# dm64lc_cslr_resz_001 register map
Vendor: Texas Instruments
Peripheral module from a debugger description file.
Registers are 32-bit, access not given, reset 0x0 unless marked. A register's access mark holds for its fields unless they carry their own. Offsets are as the file gives them; lines under a group give offsets from that group; [hi:lo] are bit positions; {n}, {i} and the like mark numbered series; 'fields as' and 'values as' point back to an identical list; <NAME> marks a mode.

## RESZ — Resizer (spec version 1.00.w.36)
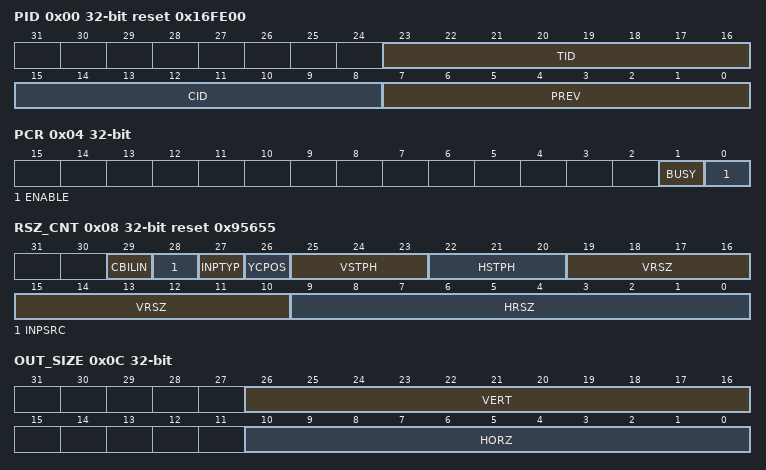
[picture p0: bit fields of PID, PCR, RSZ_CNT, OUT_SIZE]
0x00 PID reset 0x16FE00 — Peripheral Revision and Class Information
  [23:16] TID ro — Peripheral Identification Resizer module
  [15:8] CID ro — Class Identification Video processing front end
  [7:0] PREV ro — Peripheral Revision Number Initial Revision
0x04 PCR — Peripheral Control Register
  [1] BUSY ro — Busy bit
    0=NOTBUSY (No error); 1=BUSY (Error)
  [0] ENABLE rw — Enable Resizer always operates in one-shot mode; programmer must enable resizer for each frame that needs to be resized. Enable bit is reset to 0 once the busy bit turns to 1. The enable bit MUST be the last field written to resize a frame. The enable bit can be written when the resizer is busy.
    0=DISABLE (No error); 1=ENABLE (Error)
0x08 RSZ_CNT reset 0x95655 — Resizer control bits
  [29] CBILIN rw — Chrominance horizontal algorithm Filtering that is same as luminance processing is intended only for downsampling, and bilinear interpolation is intended only for upsampling.
    0=SAME_AS_LUMA (same as luminance processing); 1=BILIN_INTERP (bilinear interpolation)
  [28] INPSRC rw — Input source NOTE: If this field is set to '0' the resizer input will be fed from either the preview engine or the CCDC, but not both. The CCDC and preview engine modules have individual control to feed their output to the resizer input. If both the CCDC and preview engine modules are set to drive the resizer input, the CCDC output takes precedence.
    0=PREVIEW_OR_CCDC (Preview engine); 1=SDRAM
  [27] INPTYP rw — Input type
    0=YUV422_INTERLEAVED (YUV422 color interleaved); 1=COLOR_SEP_8BIT (color separate (8-bit data))
  [26] YCPOS rw — Luminance and chrominance position in 16-bit word
    0=YC; 1=CY
  [25:23] VSTPH rw — Vertical starting phase (0 - 7)
  [22:20] HSTPH rw — Horizontal starting phase (0 - 7)
  [19:10] VRSZ rw — Vertical resizing value (range from 64 - 1024) plus 1 Vertical resizing ratio is 256/VRSZ
  [9:0] HRSZ rw — Horizontal resizing value (range from 64 - 1024) plus 1 Horizontal resizing ratio is 256/HRSZ)
0x0C OUT_SIZE — Output width and height after resizing
  [26:16] VERT rw — Output height (in the vertical direction)
  [10:0] HORZ rw — Output (width in the horizontal direction) The maximum output width cannot be greater than 1280 pixels wide (640 if downsampling greater than 2 is used with 7 filter taps) This value must be EVEN and tne number of bytes written to SDRAM must be a multiple of 16-bytes if the vertical resizing factor is greater than 1x (upsizing)
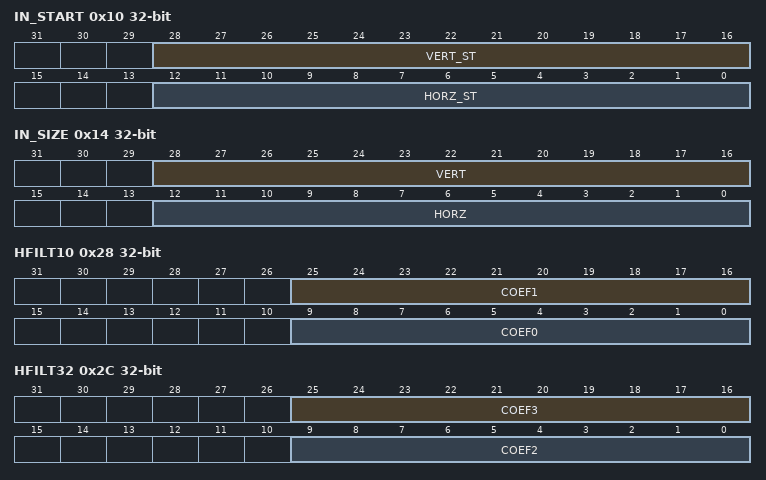
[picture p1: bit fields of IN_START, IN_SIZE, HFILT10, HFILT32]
0x10 IN_START — Input starting information
  [28:16] VERT_ST rw — Vertical starting line This field makes sense when the resizer obtains its input from the preview engine. When the resizer gets its input from SDRAM, this field must be set to 0
  [12:0] HORZ_ST rw — Horizontal starting pixel This field makes sense when the resizer obtains its input from the preview engine. When the resizer gets its input from SDRAM, this field must be set to <= 15 for YUV 16-bit data and <= 31 for 8-bit color separate data Horizontal starting pixel value is in number of pixels if input is from SDRAM. If the input to the resizer is from CCDC/preview engine, this field needs to be programmed as follows: (1) Program this field using number of bytes (twice number of pixels). (2) Change the lowest bit to reflect start position in pixels (effectively change from a value 0 to a value 1 if re-quired)
0x14 IN_SIZE — Input width and height before resizing
  [28:16] VERT rw — Input height (in the vertical direction)
  [12:0] HORZ rw — Input width (in the horizontal direction)
0x18 SDR_INADD rw — Input SDRAM address
  [31:0] SDR_INADD — Input SDRAM address The 5 LSB are treated as zeroes - should be on a 32-byte boundary * This field can be altered even when the resizer is busy. Change will take place only for the next frame. However, note that reading this register will always give the latest value.
0x1C SDR_INOFF — SDRAM offset for the input line
  [15:0] OFFSET rw — Input SDRAM address The 5 LSB are treated as zeroes - should be on a 32-byte boundary * This field can be altered even when the resizer is busy. Change will take place only for the next frame. However, note that reading this register will always give the latest value.
0x20 SDR_OUTADD rw — Output SDRAM address
  [31:0] SDR_OUTADD — Output SDRAM address The 5 LSB are treated as zeroes - should be on a 32-byte boundary For optimal use of SDRAM bandwidth, the SDRAM address should be set on a 256-byte boundary. * This field can be altered even when the resizer is busy. Change will take place only for the next frame. However, note that reading this register will always give the latest value.
0x24 SDR_OUTOFF — SDRAM offset for the output line
  [15:0] OFFSET rw — Offset of each line in the SDRAM The 5 LSB are treated as zeroes - should be on a 32-byte boundary For optimal use of SDRAM bandwidth, the SDRAM line offset should be set on a 256-byte boundary. * This field can be altered even when the resizer is busy. Change will take place only for the next frame. However, note that reading this register will always give the latest value.
0x28 HFILT10 — Horizontal filter coefficients 1 and 0
  [25:16] COEF1 rw — Coefficient - Phase 0, tap 1 (S10Q8 format -> range of -2 to 1.255/256, 1 is 0x100)
  [9:0] COEF0 rw — Coefficient - Phase 0, tap 0 (S10Q8 format -> range of -2 to 1.255/256, 1 is 0x100)
0x2C HFILT32 — Horizontal filter coefficients 3 and 2
  [25:16] COEF3 rw — Coefficient - Phase 0, tap 3 (S10Q8 format -> range of -2 to 1.255/256, 1 is 0x100)
  [9:0] COEF2 rw — Coefficient - Phase 0, tap 2 (S10Q8 format -> range of -2 to 1.255/256, 1 is 0x100)
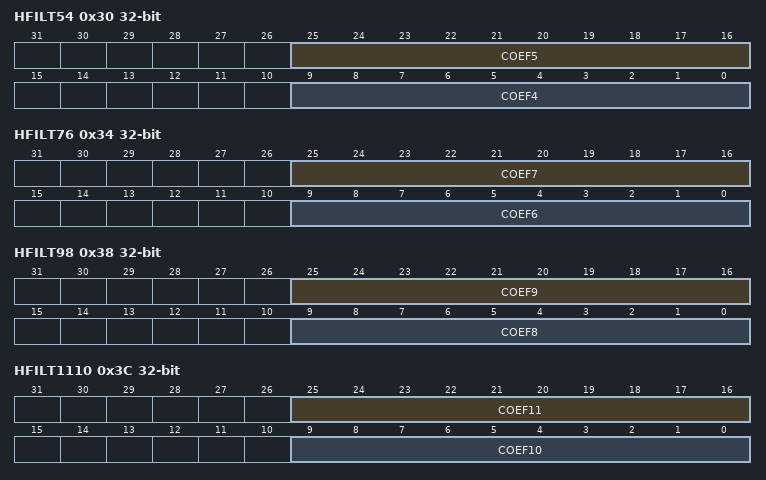
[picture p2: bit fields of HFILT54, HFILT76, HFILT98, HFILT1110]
0x30 HFILT54 — Horizontal filter coefficients 5 and 4
  [25:16] COEF5 rw — Coefficient - Phase 0/1, tap 5/1 (S10Q8 format -> range of -2 to 1.255/256, 1 is 0x100)
  [9:0] COEF4 rw — Coefficient - Phase 0/1, tap 4/0 (S10Q8 format -> range of -2 to 1.255/256, 1 is 0x100)
0x34 HFILT76 — Horizontal filter coefficients 7 and 6
  [25:16] COEF7 rw — Coefficient - Phase 0/1, tap 7/3 (S10Q8 format -> range of -2 to 1.255/256, 1 is 0x100)
  [9:0] COEF6 rw — Coefficient - Phase 0/1, tap 6/2 (S10Q8 format -> range of -2 to 1.255/256, 1 is 0x100)
0x38 HFILT98 — Horizontal filter coefficients 9 and 8
  [25:16] COEF9 rw — Coefficient) - Phase 1/2, tap 1/1 (S10Q8 format -> range of -2 to 1.255/256, 1 is 0x100)
  [9:0] COEF8 rw — Coefficient) - Phase 1/2, tap 0/0 (S10Q8 format -> range of -2 to 1.255/256, 1 is 0x100)
0x3C HFILT1110 — Horizontal filter coefficients 11 and 10
  [25:16] COEF11 rw — Coefficient) - Phase 1/2, tap 3/3 (S10Q8 format -> range of -2 to 1.255/256, 1 is 0x100)
  [9:0] COEF10 rw — Coefficient) - Phase 1/2, tap 2/2 (S10Q8 format -> range of -2 to 1.255/256, 1 is 0x100)
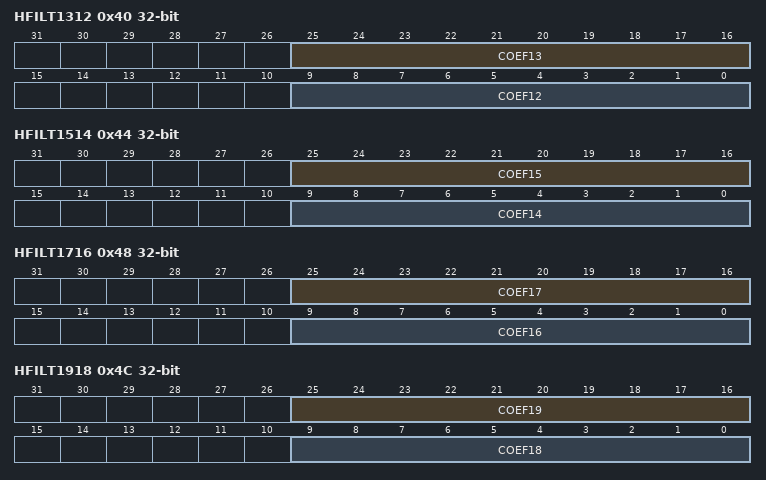
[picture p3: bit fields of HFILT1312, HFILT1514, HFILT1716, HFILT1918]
0x40 HFILT1312 — Horizontal filter coefficients 13 and 12
  [25:16] COEF13 rw — Coefficient) - Phase 1/3, tap 5/1 (S10Q8 format -> range of -2 to 1.255/256, 1 is 0x100)
  [9:0] COEF12 rw — Coefficient) - Phase 1/3, tap 4/0 (S10Q8 format -> range of -2 to 1.255/256, 1 is 0x100)
0x44 HFILT1514 — Horizontal filter coefficients 15 and 14
  [25:16] COEF15 rw — Coefficient) - Phase 1/3, tap 7/3 (S10Q8 format -> range of -2 to 1.255/256, 1 is 0x100)
  [9:0] COEF14 rw — Coefficient) - Phase 1/3, tap 6/2 (S10Q8 format -> range of -2 to 1.255/256, 1 is 0x100)
0x48 HFILT1716 — Horizontal filter coefficients 17 and 16
  [25:16] COEF17 rw — Coefficient) - Phase 2/4, tap 1/1 (S10Q8 format -> range of -2 to 1.255/256, 1 is 0x100)
  [9:0] COEF16 rw — Coefficient) - Phase 2/4, tap 0/0 (S10Q8 format -> range of -2 to 1.255/256, 1 is 0x100)
0x4C HFILT1918 — Horizontal filter coefficients 19 and 18
  [25:16] COEF19 rw — Coefficient) - Phase 2/4, tap 3/3 (S10Q8 format -> range of -2 to 1.255/256, 1 is 0x100)
  [9:0] COEF18 rw — Coefficient) - Phase 2/4, tap 2/2 (S10Q8 format -> range of -2 to 1.255/256, 1 is 0x100)
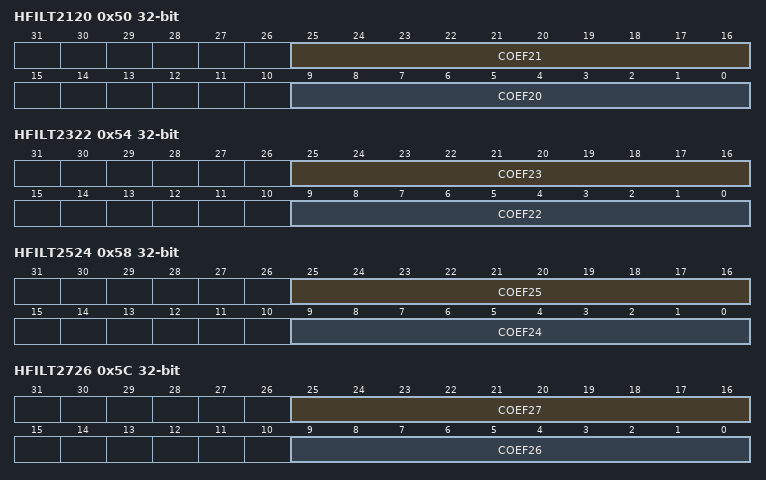
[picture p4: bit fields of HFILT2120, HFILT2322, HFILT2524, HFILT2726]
0x50 HFILT2120 — Horizontal filter coefficients 21 and 20
  [25:16] COEF21 rw — Coefficient) - Phase 2/5, tap 5/1 (S10Q8 format -> range of -2 to 1.255/256, 1 is 0x100)
  [9:0] COEF20 rw — Coefficient) - Phase 2/5, tap 4/0 (S10Q8 format -> range of -2 to 1.255/256, 1 is 0x100)
0x54 HFILT2322 — Horizontal filter coefficients 23 and 22
  [25:16] COEF23 rw — Coefficient) - Phase 2/5, tap 7/3 (S10Q8 format -> range of -2 to 1.255/256, 1 is 0x100)
  [9:0] COEF22 rw — Coefficient) - Phase 2/5, tap 6/2 (S10Q8 format -> range of -2 to 1.255/256, 1 is 0x100)
0x58 HFILT2524 — Horizontal filter coefficients 25 and 24
  [25:16] COEF25 rw — Coefficient) - Phase 3/6, tap 1/1 (S10Q8 format -> range of -2 to 1.255/256, 1 is 0x100)
  [9:0] COEF24 rw — Coefficient) - Phase 3/6, tap 0/0 (S10Q8 format -> range of -2 to 1.255/256, 1 is 0x100)
0x5C HFILT2726 — Horizontal filter coefficients 27 and 26
  [25:16] COEF27 rw — Coefficient) - Phase 3/6, tap 3/3 (S10Q8 format -> range of -2 to 1.255/256, 1 is 0x100)
  [9:0] COEF26 rw — Coefficient) - Phase 3/6, tap 2/2 (S10Q8 format -> range of -2 to 1.255/256, 1 is 0x100)
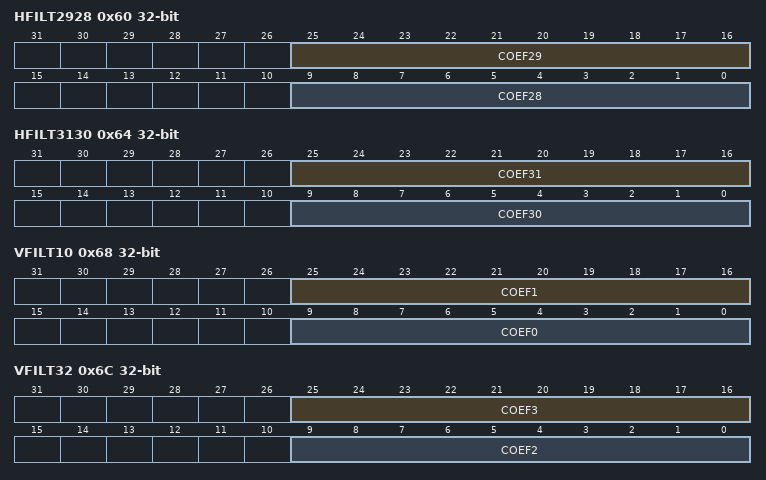
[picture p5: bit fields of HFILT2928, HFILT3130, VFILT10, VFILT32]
0x60 HFILT2928 — Horizontal filter coefficients 29 and 28
  [25:16] COEF29 rw — Coefficient) - Phase 3/7, tap 5/1 (S10Q8 format -> range of -2 to 1.255/256, 1 is 0x100)
  [9:0] COEF28 rw — Coefficient) - Phase 3/7, tap 4/0 (S10Q8 format -> range of -2 to 1.255/256, 1 is 0x100)
0x64 HFILT3130 — Horizontal filter coefficients 31 and 30
  [25:16] COEF31 rw — Coefficient) - Phase 3/7, tap 7/3 (S10Q8 format -> range of -2 to 1.255/256, 1 is 0x100)
  [9:0] COEF30 rw — Coefficient) - Phase 3/7, tap 6/2 (S10Q8 format -> range of -2 to 1.255/256, 1 is 0x100)
0x68 VFILT10 — Vertical filter coefficients 1 and 0
  [25:16] COEF1 rw — Coefficient) - Phase 0, tap 1 (S10Q8 format -> range of -2 to 1.255/256, 1 is 0x100)
  [9:0] COEF0 rw — Coefficient) - Phase 0, tap 0 (S10Q8 format -> range of -2 to 1.255/256, 1 is 0x100)
0x6C VFILT32 — Vertical filter coefficients 3 and 2
  [25:16] COEF3 rw — Coefficient) - Phase 0, tap 3 (S10Q8 format -> range of -2 to 1.255/256, 1 is 0x100)
  [9:0] COEF2 rw — Coefficient) - Phase 0, tap 2 (S10Q8 format -> range of -2 to 1.255/256, 1 is 0x100)
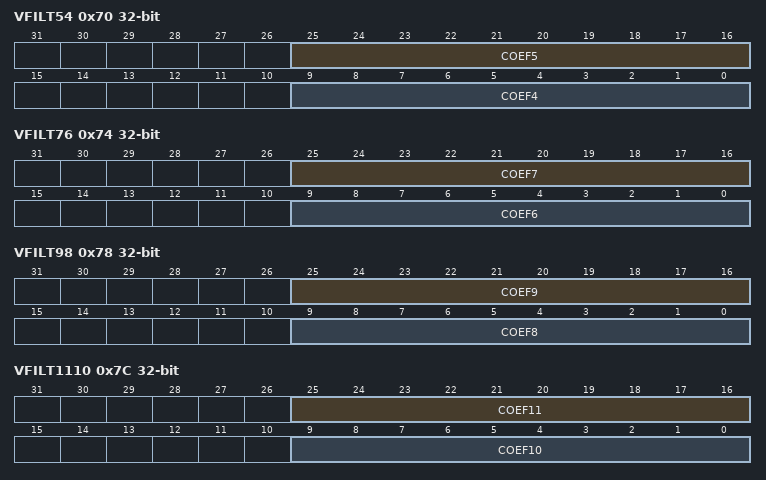
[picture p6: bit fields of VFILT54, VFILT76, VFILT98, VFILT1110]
0x70 VFILT54 — Vertical filter coefficients 5 and 4
  [25:16] COEF5 rw — Coefficient) - Phase 0/1, tap 5/1 (S10Q8 format -> range of -2 to 1.255/256, 1 is 0x100)
  [9:0] COEF4 rw — Coefficient) - Phase 0/1, tap 4/0 (S10Q8 format -> range of -2 to 1.255/256, 1 is 0x100)
0x74 VFILT76 — Vertical filter coefficients 7 and 6
  [25:16] COEF7 rw — Coefficient) - Phase 0/1, tap 7/3 (S10Q8 format -> range of -2 to 1.255/256, 1 is 0x100)
  [9:0] COEF6 rw — Coefficient) - Phase 0/1, tap 6/2 (S10Q8 format -> range of -2 to 1.255/256, 1 is 0x100)
0x78 VFILT98 — Vertical filter coefficients 9 and 8
  fields as HFILT98
0x7C VFILT1110 — Vertical filter coefficients 11 and 10
  fields as HFILT1110
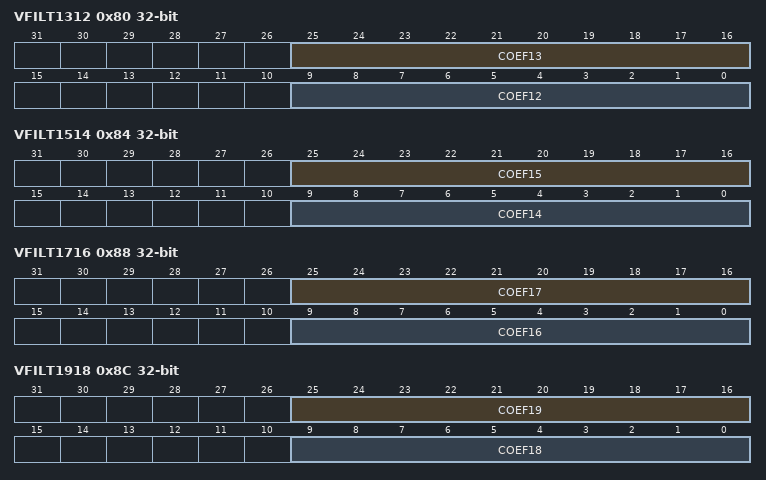
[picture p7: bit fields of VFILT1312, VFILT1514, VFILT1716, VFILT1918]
0x80 VFILT1312 — Vertical filter coefficients 13 and 12
  fields as HFILT1312
0x84 VFILT1514 — Vertical filter coefficients 15 and 14
  fields as HFILT1514
0x88 VFILT1716 — Vertical filter coefficients 17 and 16
  fields as HFILT1716
0x8C VFILT1918 — Vertical filter coefficients 19 and 18
  fields as HFILT1918
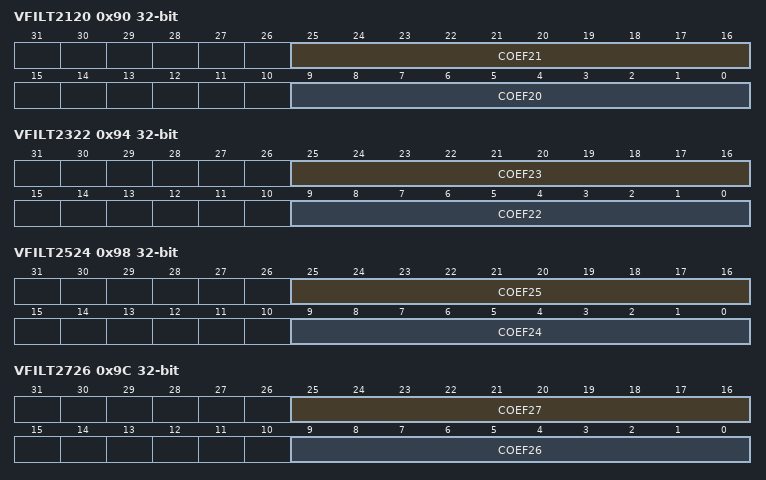
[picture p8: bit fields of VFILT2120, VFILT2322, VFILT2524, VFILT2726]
0x90 VFILT2120 — Vertical filter coefficients 21 and 20
  fields as HFILT2120
0x94 VFILT2322 — Vertical filter coefficients 23 and 22
  fields as HFILT2322
0x98 VFILT2524 — Vertical filter coefficients 25 and 24
  fields as HFILT2524
0x9C VFILT2726 — Vertical filter coefficients 27 and 26
  fields as HFILT2726
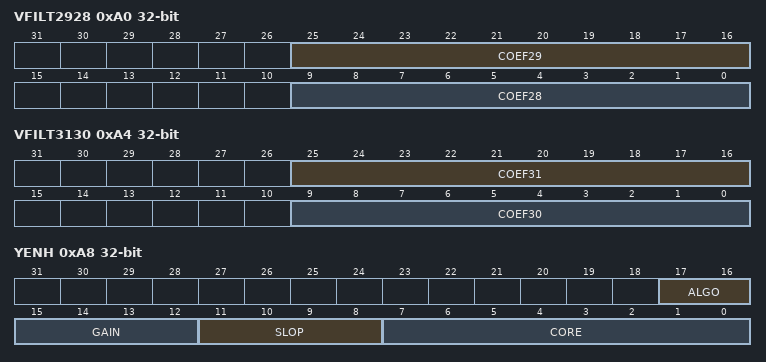
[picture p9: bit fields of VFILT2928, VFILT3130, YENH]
0xA0 VFILT2928 — Vertical filter coefficients 29 and 28
  fields as HFILT2928
0xA4 VFILT3130 — Vertical filter coefficients 31 and 30
  fields as HFILT3130
0xA8 YENH — Luminance enhancer
  [17:16] ALGO rw — Luminance Algorithm hpgain = (|HPF(Y)| - CORE) * SLOP saturate hpgain between 0 and gain Y' = Y + (HPF(Y) * hpgain + 8) >> 4 saturate Y' between 0 and 255
    0=DISABLE; 1=HPF_3TAP ([-1 2 -1]/2 HPF); 2=HPF_5TAP ([-1 -2 6 -2 -1]/4 HPF)
  [15:12] GAIN rw — Max gain (U4Q4)
  [11:8] SLOP rw — Slope (U4Q4)
  [7:0] CORE rw — Coring offset (U8Q0)
